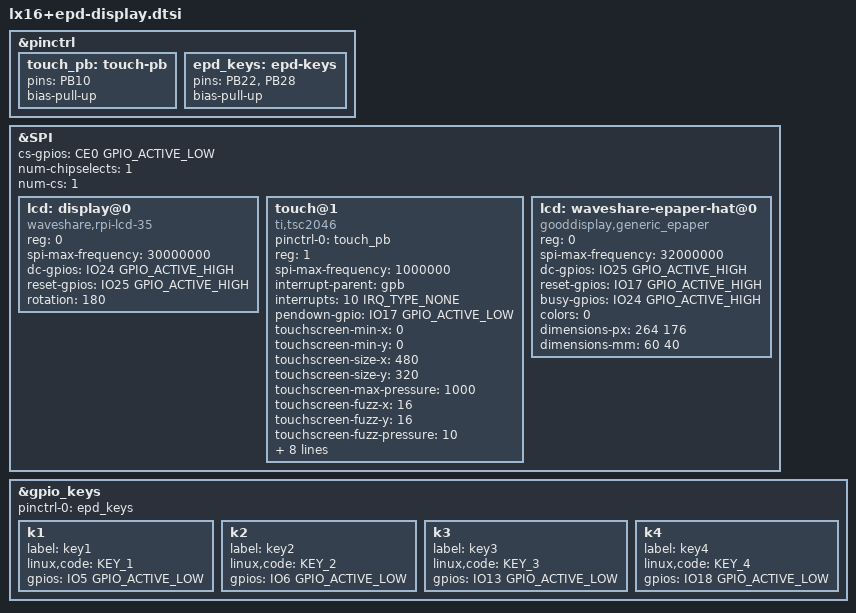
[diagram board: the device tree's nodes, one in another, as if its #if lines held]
/* Application connected to RasPi compatible Header */

#if APPLICATION == 1

&pinctrl {
	touch_pb: touch-pb {
		pins = "PB10";	// IO17 = PB10 pull up
		bias-pull-up;
	};
};

&SPI {
	/* https://www.waveshare.com/wiki/3.5inch_RPi_LCD_(A)#Interface_Definition */

	cs-gpios = <CE0 GPIO_ACTIVE_LOW>, <CE1 GPIO_ACTIVE_LOW>;
	num-chipselects = <2>;
	num-cs = <0>;	// do not use internal CS

        lcd: display@0 {
		compatible = "waveshare,rpi-lcd-35", "ilitek,ili9486";
		reg = <0>;	/* CS0 */

//		spi-max-frequency = <54000000>;
//		spi-max-frequency = <10000000>;
		spi-max-frequency = <30000000>;

		dc-gpios = <IO24 GPIO_ACTIVE_HIGH>;
		reset-gpios = <IO25 GPIO_ACTIVE_HIGH>;

		rotation = <180>;
	};

	touch@1 {
		pinctrl-names = "default";
		pinctrl-0 = <&touch_pb>;

		compatible = "ti,tsc2046";
		reg = <1>;	/* CS1 */

		spi-max-frequency = <1000000>;

		interrupt-parent = <&gpb>;
		interrupts = <10 IRQ_TYPE_NONE>;	/* IO17 = pb10 */
		pendown-gpio = <IO17 GPIO_ACTIVE_LOW>;

		touchscreen-min-x = <0>;
		touchscreen-min-y = <0>;
		touchscreen-size-x = <480>;
		touchscreen-size-y = <320>;
		touchscreen-max-pressure = <1000>;
		touchscreen-fuzz-x = <16>;
		touchscreen-fuzz-y = <16>;
		touchscreen-fuzz-pressure = <10>;
		touchscreen-inverted-x;
		// touchscreen-inverted-y;

		ti,x-min = /bits/ 16 <160>;
		ti,x-max = /bits/ 16 <3900>;
		ti,y-min = /bits/ 16 <220>;
		ti,y-max = /bits/ 16 <3750>;
		ti,x-plate-ohms = /bits/ 16 <40>;
		ti,pressure-max = /bits/ 16 <255>;

		wakeup-source;
	};
};

#endif

#if APPLICATION == 2

&pinctrl {
	epd_keys: epd-keys {
		pins = "PB22", "PB28" /* the following can only pull down! , "PC2", PC26" */;
		bias-pull-up;
	};
};

&SPI {
	/* https://www.waveshare.com/wiki/2.7inch_e-Paper_HAT_Manual#Resources */

	cs-gpios = <CE0 GPIO_ACTIVE_LOW>;
	num-chipselects = <1>;
	num-cs = <1>;

	lcd: waveshare-epaper-hat@0 {
		compatible = "gooddisplay,generic_epaper";
		reg = <0>;
		spi-max-frequency = <32000000>;

		dc-gpios = <IO25 GPIO_ACTIVE_HIGH>;
		reset-gpios = <IO17 GPIO_ACTIVE_HIGH>;
		busy-gpios = <IO24 GPIO_ACTIVE_HIGH>;

//		spi-speed-hz = <1000000>;
		// partial-update;
		// mirror-x;
		// mirror-y;
		// many more...
		colors = <0>;
		dimensions-px = <264 176>;
		dimensions-mm = <60 40>;
	};
};

&gpio_keys {
		pinctrl-names = "default";
		pinctrl-0 = <&epd_keys>;

		k1 {
			label = "key1";
			linux,code = <KEY_1>;
			gpios = <IO5 GPIO_ACTIVE_LOW>;	// has no pullup!
		};

		k2 {
			label = "key2";
			linux,code = <KEY_2>;
			gpios = <IO6 GPIO_ACTIVE_LOW>;
		};

		k3 {
			label = "key3";
			linux,code = <KEY_3>;
			gpios = <IO13 GPIO_ACTIVE_LOW>;	// has no pullup!
		};

		k4 {
			label = "key4";
			linux,code = <KEY_4>;
			gpios = <IO18 GPIO_ACTIVE_LOW>;
		};
};

#endif
